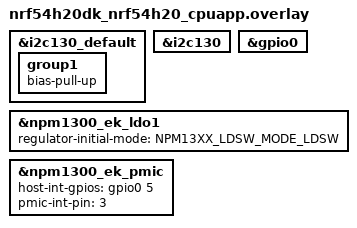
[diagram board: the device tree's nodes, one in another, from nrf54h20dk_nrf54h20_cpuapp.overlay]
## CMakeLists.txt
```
# Copyright (c) 2023 Nordic Semiconductor ASA
# SPDX-License-Identifier: LicenseRef-Nordic-5-Clause

cmake_minimum_required(VERSION 3.20.0)

list(APPEND BOARD_ROOT ${CMAKE_CURRENT_SOURCE_DIR})

set(SHIELD npm1300_ek)

find_package(Zephyr REQUIRED HINTS $ENV{ZEPHYR_BASE})

project(npm1300_one_button)

add_subdirectory(src)
```

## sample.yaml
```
# Copyright (c) 2023 Nordic Semiconductor ASA
# SPDX-License-Identifier: LicenseRef-Nordic-5-Clause
sample:
  name: nPM1300 one button

common:
  integration_platforms:
    - nrf52dk/nrf52832
    - nrf52840dk/nrf52840
    - nrf5340dk/nrf5340/cpuapp
    - nrf54l15dk/nrf54l15/cpuapp
    - nrf54lm20dk/nrf54lm20a/cpuapp
    - nrf54h20dk/nrf54h20/cpuapp
    - nrf9160dk/nrf9160
  platform_allow:
    - nrf52dk/nrf52832
    - nrf52840dk/nrf52840
    - nrf5340dk/nrf5340/cpuapp
    - nrf54l15dk/nrf54l15/cpuapp
    - nrf54lm20dk/nrf54lm20a/cpuapp
    - nrf54h20dk/nrf54h20/cpuapp
    - nrf9160dk/nrf9160
  tags:
    - pmic
    - ci_samples_pmic
tests:
  sample.npm1300_one_button_compile:
    sysbuild: true
    build_only: true
    platform_allow:
      - nrf52dk/nrf52832
      - nrf52840dk/nrf52840
      - nrf5340dk/nrf5340/cpuapp
      - nrf54l15dk/nrf54l15/cpuapp
      - nrf54lm20dk/nrf54lm20a/cpuapp
      - nrf54h20dk/nrf54h20/cpuapp
      - nrf9160dk/nrf9160
    tags:
      - shield
      - sysbuild
      - ci_samples_pmic
```

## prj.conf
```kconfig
# Copyright (c) 2023 Nordic Semiconductor ASA
# SPDX-License-Identifier: LicenseRef-Nordic-5-Clause

CONFIG_SHELL=y
CONFIG_LOG=y
CONFIG_LED=y
CONFIG_GPIO=y
CONFIG_REGULATOR=y
CONFIG_SENSOR=y
CONFIG_I2C_SHELL=y
CONFIG_LOG_CMDS=y
```

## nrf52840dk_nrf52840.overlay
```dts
/*
 * Copyright (c) 2023 Nordic Semiconductor ASA
 *
 * SPDX-License-Identifier: LicenseRef-Nordic-5-Clause
 */

#include <dt-bindings/regulator/npm1300.h>

&i2c0_default {
	group1 {
		bias-pull-up;
	};
};

&npm1300_ek_ldo1 {
	regulator-initial-mode = <NPM1300_LDSW_MODE_LDSW>;
};

&npm1300_ek_pmic {
	host-int-gpios = <&gpio1 12 0>;
	pmic-int-pin = <3>;
};
```

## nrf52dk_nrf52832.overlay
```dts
/*
 * Copyright (c) 2023 Nordic Semiconductor ASA
 *
 * SPDX-License-Identifier: LicenseRef-Nordic-5-Clause
 */

#include <dt-bindings/regulator/npm1300.h>

&i2c0_default {
	group1 {
		bias-pull-up;
	};
};

&npm1300_ek_ldo1 {
	regulator-initial-mode = <NPM1300_LDSW_MODE_LDSW>;
};

&npm1300_ek_pmic {
	host-int-gpios = <&gpio0 22 0>;
	pmic-int-pin = <3>;
};
```

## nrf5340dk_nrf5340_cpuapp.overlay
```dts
/*
 * Copyright (c) 2023 Nordic Semiconductor ASA
 *
 * SPDX-License-Identifier: LicenseRef-Nordic-5-Clause
 */

#include <dt-bindings/regulator/npm13xx.h>

&i2c1_default {
	group1 {
		bias-pull-up;
	};
};

&npm1300_ek_ldo1 {
	regulator-initial-mode = <NPM13XX_LDSW_MODE_LDSW>;
};

&npm1300_ek_pmic {
	host-int-gpios = <&gpio1 12 0>;
	pmic-int-pin = <3>;
};
```

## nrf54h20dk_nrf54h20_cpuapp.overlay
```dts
/*
 * Copyright (c) 2024 Nordic Semiconductor ASA
 *
 * SPDX-License-Identifier: LicenseRef-Nordic-5-Clause
 */

 #include <dt-bindings/regulator/npm13xx.h>

&i2c130_default {
	group1 {
		bias-pull-up;
	};
};

&i2c130 {
	status = "okay";
};

&gpio0 {
	status = "okay";
};

&npm1300_ek_ldo1 {
	regulator-initial-mode = <NPM13XX_LDSW_MODE_LDSW>;
};

&npm1300_ek_pmic {
	host-int-gpios = <&gpio0 5 0>;
	pmic-int-pin = <3>;
};
```

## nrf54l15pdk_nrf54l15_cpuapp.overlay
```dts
/*
 * Copyright (c) 2024 Nordic Semiconductor ASA
 *
 * SPDX-License-Identifier: LicenseRef-Nordic-5-Clause
 */

#include <dt-bindings/regulator/npm1300.h>

&i2c21_default {
	group1 {
		bias-pull-up;
	};
};

&i2c21 {
	status = "okay";
};

&npm1300_ek_ldo1 {
	regulator-initial-mode = <NPM1300_LDSW_MODE_LDSW>;
};

&npm1300_ek_pmic {
	host-int-gpios = <&gpio1 10 0>;
	pmic-int-pin = <3>;
};
```

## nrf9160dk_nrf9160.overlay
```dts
/*
 * Copyright (c) 2023 Nordic Semiconductor ASA
 *
 * SPDX-License-Identifier: LicenseRef-Nordic-5-Clause
 */

#include <dt-bindings/regulator/npm13xx.h>

&i2c2_default {
	group1 {
		bias-pull-up;
	};
};

&npm1300_ek_ldo1 {
	regulator-initial-mode = <NPM13XX_LDSW_MODE_LDSW>;
};

&npm1300_ek_pmic {
	host-int-gpios = <&gpio0 10 0>;
	pmic-int-pin = <3>;
};
```

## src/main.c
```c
/*
 * Copyright (c) 2023 Nordic Semiconductor ASA
 * SPDX-License-Identifier: LicenseRef-Nordic-5-Clause
 */

#include <stdlib.h>

#include <zephyr/kernel.h>
#include <zephyr/device.h>
#include <zephyr/drivers/gpio.h>
#include <zephyr/drivers/led.h>
#include <zephyr/drivers/mfd/npm13xx.h>
#include <zephyr/drivers/regulator.h>
#include <zephyr/drivers/sensor.h>
#include <zephyr/sys/printk.h>

#define FAST_FLASH_MS	100
#define SLOW_FLASH_MS	500
#define PRESS_SHORT_MS	1000
#define PRESS_MEDIUM_MS 5000

static volatile int flash_time_ms = SLOW_FLASH_MS;
static volatile bool vbus_connected;

static const struct device *pmic = DEVICE_DT_GET(DT_NODELABEL(npm1300_ek_pmic));
static const struct device *leds = DEVICE_DT_GET(DT_NODELABEL(npm1300_ek_leds));
static const struct device *regulators = DEVICE_DT_GET(DT_NODELABEL(npm1300_ek_regulators));
static const struct device *ldsw = DEVICE_DT_GET(DT_NODELABEL(npm1300_ek_ldo1));
static const struct device *charger = DEVICE_DT_GET(DT_NODELABEL(npm1300_ek_charger));

static void event_callback(const struct device *dev, struct gpio_callback *cb, uint32_t pins)
{
	static int press_t;

	if (pins & BIT(NPM13XX_EVENT_SHIPHOLD_PRESS)) {
		press_t = k_uptime_get();
	}

	if (pins & BIT(NPM13XX_EVENT_SHIPHOLD_RELEASE)) {
		press_t = k_uptime_get() - press_t;

		if (press_t < PRESS_SHORT_MS) {
			printk("Short press\n");
			if (!regulator_is_enabled(ldsw)) {
				regulator_enable(ldsw);
			}
			flash_time_ms = FAST_FLASH_MS;
		} else if (press_t < PRESS_MEDIUM_MS) {
			printk("Medium press\n");
			if (regulator_is_enabled(ldsw)) {
				regulator_disable(ldsw);
			}
			flash_time_ms = SLOW_FLASH_MS;
		} else {
			printk("Long press\n");
			if (vbus_connected) {
				printk("Ship mode entry not possible with USB connected\n");
			} else {
				regulator_parent_ship_mode(regulators);
			}
		}
	}

	if (pins & BIT(NPM13XX_EVENT_VBUS_DETECTED)) {
		printk("Vbus connected\n");
		vbus_connected = true;
	}

	if (pins & BIT(NPM13XX_EVENT_VBUS_REMOVED)) {
		printk("Vbus removed\n");
		vbus_connected = false;
	}
}

bool configure_events(void)
{
	if (!device_is_ready(pmic)) {
		printk("Pmic device not ready.\n");
		return false;
	}

	if (!device_is_ready(regulators)) {
		printk("Regulator device not ready.\n");
		return false;
	}

	if (!device_is_ready(ldsw)) {
		printk("Load switch device not ready.\n");
		return false;
	}

	if (!device_is_ready(charger)) {
		printk("Charger device not ready.\n");
		return false;
	}

	static struct gpio_callback event_cb;

	gpio_init_callback(&event_cb, event_callback,
			   BIT(NPM13XX_EVENT_SHIPHOLD_PRESS) | BIT(NPM13XX_EVENT_SHIPHOLD_RELEASE) |
				   BIT(NPM13XX_EVENT_VBUS_DETECTED) |
				   BIT(NPM13XX_EVENT_VBUS_REMOVED));

	mfd_npm13xx_add_callback(pmic, &event_cb);

	/* Initialise vbus detection status */
	struct sensor_value val;
	int ret = sensor_attr_get(charger, SENSOR_CHAN_CURRENT, SENSOR_ATTR_UPPER_THRESH, &val);

	if (ret < 0) {
		return false;
	}

	vbus_connected = (val.val1 != 0) || (val.val2 != 0);

	return true;
}

int main(void)
{
	if (!device_is_ready(leds)) {
		printk("Error: led device is not ready\n");
		return 0;
	}

	if (!configure_events()) {
		printk("Error: could not configure events\n");
		return 0;
	}

	printk("PMIC device ok\n");

	while (1) {
		led_on(leds, 2U);
		k_msleep(flash_time_ms);
		led_off(leds, 2U);
		k_msleep(flash_time_ms);
	}
}
```
